AUTOSAR XML (schema 4-0-3)
package /ComponentTypes
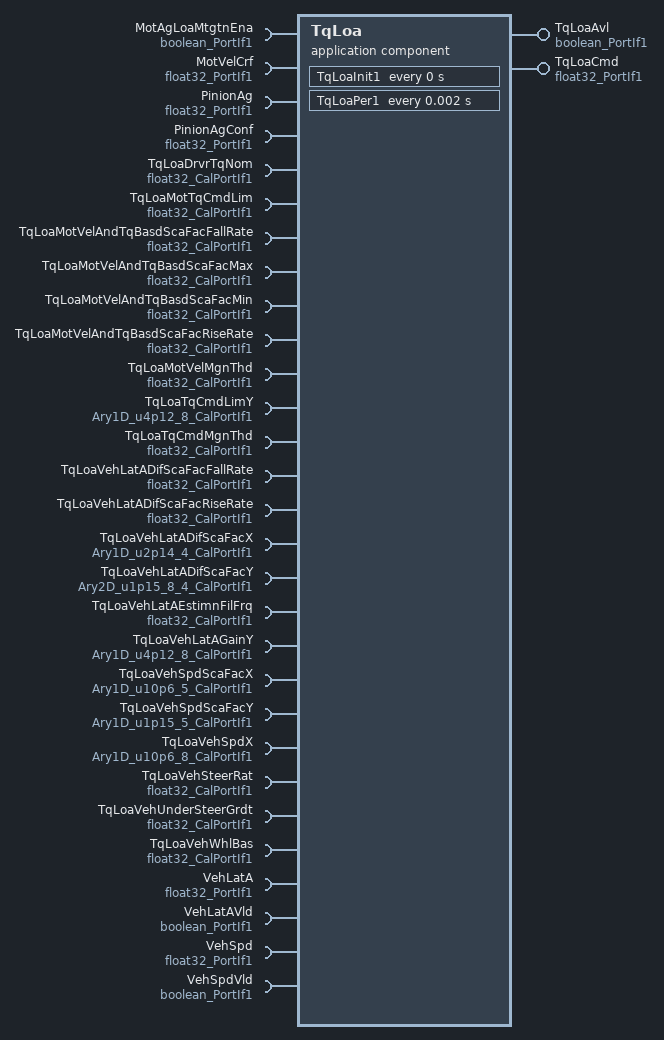
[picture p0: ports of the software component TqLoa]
  application sw component type TqLoa
    provide port TqLoaAvl: nonqueued-sender-com-spec{data-element=Logl, init-value=0}, provided-interface=boolean_PortIf1
    provide port TqLoaCmd: nonqueued-sender-com-spec{data-element=Val, init-value=0}, provided-interface=float32_PortIf1
    29 x require port:
      MotAgLoaMtgtnEna: nonqueued-receiver-com-spec{data-element=Logl, filter=data-filter-type=ALWAYS, init-value=0}, required-interface=boolean_PortIf1
      MotVelCrf: nonqueued-receiver-com-spec{data-element=Val, filter=data-filter-type=ALWAYS, init-value=0}, required-interface=float32_PortIf1
      PinionAg: nonqueued-receiver-com-spec{data-element=Val, filter=data-filter-type=ALWAYS, init-value=0}, required-interface=float32_PortIf1
      PinionAgConf: nonqueued-receiver-com-spec{data-element=Val, filter=data-filter-type=ALWAYS, init-value=0}, required-interface=float32_PortIf1
      TqLoaDrvrTqNom: parameter-require-com-spec{init-value=0.0117, parameter=Val}, required-interface=float32_CalPortIf1
      TqLoaMotTqCmdLim: parameter-require-com-spec{init-value=4.5, parameter=Val}, required-interface=float32_CalPortIf1
      TqLoaMotVelAndTqBasdScaFacFallRate: parameter-require-com-spec{init-value=-15.625, parameter=Val}, required-interface=float32_CalPortIf1
      TqLoaMotVelAndTqBasdScaFacMax: parameter-require-com-spec{init-value=1, parameter=Val}, required-interface=float32_CalPortIf1
      TqLoaMotVelAndTqBasdScaFacMin: parameter-require-com-spec{init-value=0.75, parameter=Val}, required-interface=float32_CalPortIf1
      TqLoaMotVelAndTqBasdScaFacRiseRate: parameter-require-com-spec{init-value=7.8125, parameter=Val}, required-interface=float32_CalPortIf1
      TqLoaMotVelMgnThd: parameter-require-com-spec{init-value=1.908, parameter=Val}, required-interface=float32_CalPortIf1
      TqLoaTqCmdLimY: parameter-require-com-spec{init-value=[2880, 2880, 2880, 2240, 1664, 1408, 1216, 832], parameter=Ary1D}, required-interface=Ary1D_u4p12_8_CalPortIf1
      TqLoaTqCmdMgnThd: parameter-require-com-spec{init-value=0, parameter=Val}, required-interface=float32_CalPortIf1
      TqLoaVehLatADifScaFacFallRate: parameter-require-com-spec{init-value=-4, parameter=Val}, required-interface=float32_CalPortIf1
      TqLoaVehLatADifScaFacRiseRate: parameter-require-com-spec{init-value=0.1, parameter=Val}, required-interface=float32_CalPortIf1
      TqLoaVehLatADifScaFacX: parameter-require-com-spec{init-value=[0, 2293, 5242, 16384], parameter=Ary1D}, required-interface=Ary1D_u2p14_4_CalPortIf1
      TqLoaVehLatADifScaFacY: parameter-require-com-spec{init-value=8 x [32768, 32768, 0, 0], parameter=Ary2D}, required-interface=Ary2D_u1p15_8_4_CalPortIf1
      TqLoaVehLatAEstimnFilFrq: parameter-require-com-spec{init-value=2, parameter=Val}, required-interface=float32_CalPortIf1
      TqLoaVehLatAGainY: parameter-require-com-spec{init-value=[0, 6144, 9920, 6784, 4928, 3968, 3520, 384], parameter=Ary1D}, required-interface=Ary1D_u4p12_8_CalPortIf1
      TqLoaVehSpdScaFacX: parameter-require-com-spec{init-value=[320, 640, 1920, 3840, 6400], parameter=Ary1D}, required-interface=Ary1D_u10p6_5_CalPortIf1
      TqLoaVehSpdScaFacY: parameter-require-com-spec{init-value=[0, 32768, 32768, 32768, 32768], parameter=Ary1D}, required-interface=Ary1D_u1p15_5_CalPortIf1
      TqLoaVehSpdX: parameter-require-com-spec{init-value=[320, 640, 1280, 1920, 2560, 3200, 3840, 7680], parameter=Ary1D}, required-interface=Ary1D_u10p6_8_CalPortIf1
      TqLoaVehSteerRat: parameter-require-com-spec{init-value=16, parameter=Val}, required-interface=float32_CalPortIf1
      TqLoaVehUnderSteerGrdt: parameter-require-com-spec{init-value=0.0211, parameter=Val}, required-interface=float32_CalPortIf1
      TqLoaVehWhlBas: parameter-require-com-spec{init-value=2.7305, parameter=Val}, required-interface=float32_CalPortIf1
      VehLatA: nonqueued-receiver-com-spec{data-element=Val, filter=data-filter-type=ALWAYS, init-value=0}, required-interface=float32_PortIf1
      VehLatAVld: nonqueued-receiver-com-spec{data-element=Logl, filter=data-filter-type=ALWAYS, init-value=0}, required-interface=boolean_PortIf1
      VehSpd: nonqueued-receiver-com-spec{data-element=Val, filter=data-filter-type=ALWAYS, init-value=0}, required-interface=float32_PortIf1
      VehSpdVld: nonqueued-receiver-com-spec{data-element=Logl, filter=data-filter-type=ALWAYS, init-value=0}, required-interface=boolean_PortIf1
    behavior TqLoa_InternalBehavior
      ar-typed-per-instance-memorys:
        10 x data, all with sw-calibration-access=READ-ONLY:
          dTqLoaMotTqCmdPreScag: type=float32
          dTqLoaMotVelAndTqBasdScaFac: type=float32
          dTqLoaScaFacFinal: type=float32
          dTqLoaVehLatADifScaFac: type=float32
          dTqLoaVehLatAEstimn: type=float32
          dTqLoaVehSpdBasdScaFac: type=float32
          MotTqCmdPrev: type=float32
          MotVelAndTqBasdScaFacPrev: type=float32
          VehLatADifScaFacPrev: type=float32
          VehLatAEstimnFil: type=FilLpRec1
      timing event TqLoa_InitEvent: start-on-event=TqLoaInit1, period=0
      timing event TMT_TqLoaPer1: start-on-event=TqLoaPer1, period=0.002
      runnable TqLoaInit1
      runnable TqLoaPer1
        data-receive-point-by-arguments:
          8 x access:
            REC_HwAgAuthy_Val: accessed-variable=PinionAgConf.Val
            REC_HwAgRel_Val: accessed-variable=PinionAg.Val
            REC_MotAgLoaMtgtnEna_Logl: accessed-variable=MotAgLoaMtgtnEna.Logl
            REC_MotVelCrf_Val: accessed-variable=MotVelCrf.Val
            REC_VehLatA_Val: accessed-variable=VehLatA.Val
            REC_VehLatAVld_Logl: accessed-variable=VehLatAVld.Logl
            REC_VehSpd_Val: accessed-variable=VehSpd.Val
            REC_VehSpdVld_Logl: accessed-variable=VehSpdVld.Logl
        data-send-points:
          access SEND_TqLoaAvl_Logl: accessed-variable=TqLoaAvl.Logl
          access SEND_TqLoaCmd_Val: accessed-variable=TqLoaCmd.Val
  swc implementation TqLoa_Implementation: behavior=TqLoa_InternalBehavior
    code-descriptors:
      code Default: artifact-descriptors=autosar-engineering-object={short-label=Default, category=SWSRC}
